# STM32U5Fx register map
File version: 1.0
CPU: CM33 r0p1, little endian, MPU, FPU, 4 interrupt priority bits
Registers are 32-bit, read-write, reset 0x0 unless marked. A register's access mark holds for its fields unless they carry their own. Offsets are from the block's base; [hi:lo] are bit positions; {n}, {i} and the like mark numbered series; 'fields as' and 'values as' point back to an identical list.

## FLASH
Base 0x40022000
Same registers: SEC_FLASH 0x50022000
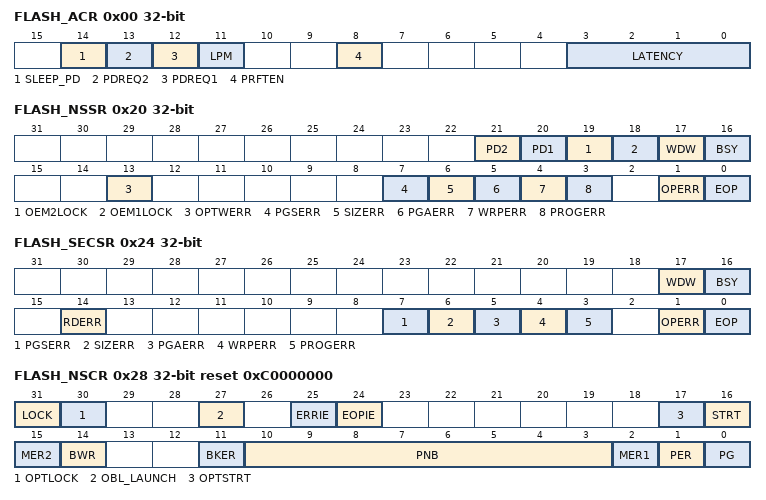
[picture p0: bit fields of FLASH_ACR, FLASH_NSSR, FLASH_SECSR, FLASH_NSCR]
0x00 FLASH_ACR — FLASH access control register
  [14] SLEEP_PD — Flash memory power-down mode during Sleep mode This bit determines whether the Flash memory is in power-down mode or Idle mode when the device is in Sleep mode. The Flash must not be put in power-down while a program or an erase operation is on-going.
    0=Flash in Idle mode during Sleep mode; 1=Flash in power-down mode during Sleep mode
  [13] PDREQ2 — Bank 2 power-down mode request This bit is write-protected with FLASH_PDKEY2R. This bit requests bank 2 to enter power-down mode. When bank 2 enters power-down mode, this bit is cleared by hardware and the PDKEY2R is locked.
    0=No request for bank 2 to enter power-down mode; 1=Bank 2 requested to enter power-down mode
  [12] PDREQ1 — Bank 1 power-down mode request This bit is write-protected with FLASH_PDKEY1R. This bit requests bank 1 to enter power-down mode. When bank 1 enters power-down mode, this bit is cleared by hardware and the PDKEY1R is locked.
    0=No request for bank 1 to enter power-down mode; 1=Bank 1 requested to enter power-down mode
  [11] LPM — Low-power read mode This bit puts the Flash memory in low-power read mode.
    0=Flash not in low-power read mode; 1=Flash in low-power read mode
  [8] PRFTEN — Prefetch enable This bit enables the prefetch buffer in the embedded Flash memory.
    0=Prefetch disabled; 1=Prefetch enabled
  [3:0] LATENCY — Latency These bits represent the ratio between the HCLK (AHB clock) period and the Flash memory access time. ...
    0=Zero wait state; 1=One wait state; 2=Two wait states; 15=Fifteen wait states
0x08 FLASH_NSKEYR wo — FLASH non-secure key register
  [31:0] NSKEY — Flash memory non-secure key The following values must be written consecutively to unlock the FLASH_NSCR register, allowing the Flash memory non-secure programming/erasing operations: KEY1: 0x4567 0123 KEY2: 0xCDEF 89AB
0x0C FLASH_SECKEYR wo — FLASH secure key register
  [31:0] SECKEY — Flash memory secure key The following values must be written consecutively to unlock the FLASH_SECCR register, allowing the Flash memory secure programming/erasing operations: KEY1: 0x4567 0123 KEY2: 0xCDEF 89AB
0x10 FLASH_OPTKEYR wo — FLASH option key register
  [31:0] OPTKEY — Option byte key The following values must be written consecutively to unlock the FLASH_OPTR register allowing option byte programming/erasing operations: KEY1: 0x0819 2A3B KEY2: 0x4C5D 6E7F
0x18 FLASH_PDKEY1R wo — FLASH bank 1 power-down key register
  [31:0] PDKEY1 — Bank 1 power-down key The following values must be written consecutively to unlock the PDREQ1 bit in FLASH_ACR: PDKEY1_1: 0x0415 2637 PDKEY1_2: 0xFAFB FCFD
0x1C FLASH_PDKEY2R wo — FLASH bank 2 power-down key register
  [31:0] PDKEY2 — Bank 2 power-down key The following values must be written consecutively to unlock the PDREQ2 bit in FLASH_ACR: PDKEY2_1: 0x4051 6273 PDKEY2_2: 0xAFBF CFDF
0x20 FLASH_NSSR (reset mask 0xFFF0FFFF) — FLASH non-secure status register
  [21] PD2 ro — Bank 2 in power-down mode This bit indicates that the Flash memory bank 2 is in power-down state. It is reset when bank 2 is in normal mode or being awaken.
  [20] PD1 ro — Bank 1 in power-down mode This bit indicates that the Flash memory bank 1 is in power-down state. It is reset when bank 1 is in normal mode or being awaken.
  [19] OEM2LOCK ro — OEM2 lock This bit indicates that the OEM2 RDP key read during the OBL is not virgin. When set, the OEM2 RDP lock mechanism is active.
  [18] OEM1LOCK ro — OEM1 lock This bit indicates that the OEM1 RDP key read during the OBL is not virgin. When set, the OEM1 RDP lock mechanism is active.
  [17] WDW ro — Non-secure wait data to write This bit indicates that the Flash memory write buffer has been written by a secure or non-secure operation. It is set when the first data is stored in the buffer and cleared when the write is performed in the Flash memory.
  [16] BSY ro — Non-secure busy This indicates that a Flash memory secure or non-secure operation is in progress. This bit is set at the beginning of a Flash operation and reset when the operation finishes or when an error occurs.
  [13] OPTWERR — Option write error This bit is set by hardware when the options bytes are written with an invalid configuration. It is cleared by writing 1. Refer to for full conditions of error flag setting.
  [7] PGSERR — Non-secure programming sequence error This bit is set by hardware when programming sequence is not correct. It is cleared by writing 1. Refer to for full conditions of error flag setting.
  [6] SIZERR — Non-secure size error This bit is set by hardware when the size of the access is a byte or half-word during a non-secure program sequence. Only quad-word programming is allowed by means of successive word accesses. This bit is cleared by writing 1.
  [5] PGAERR — Non-secure programming alignment error This bit is set by hardware when the first word to be programmed is not aligned with a quad-word address, or the second, third or forth word does not belong to the same quad-word address. This bit is cleared by writing 1.
  [4] WRPERR — Non-secure write protection error This bit is set by hardware when an non-secure address to be erased/programmed belongs to a write-protected part (by WRP, PCROP, HDP or RDP level 1) of the Flash memory. This bit is cleared by writing 1. Refer to for full conditions of error flag setting.
  [3] PROGERR — Non-secure programming error This bit is set by hardware when a non-secure quad-word address to be programmed contains a value different from all 1 before programming, except if the data to write is all 0. This bit is cleared by writing 1.
  [1] OPERR — Non-secure operation error This bit is set by hardware when a Flash memory non-secure operation (program/erase) completes unsuccessfully. This bit is set only if non-secure error interrupts are enabled (NSERRIE = 1). This bit is cleared by writing 1.
  [0] EOP — Non-secure end of operation This bit is set by hardware when one or more Flash memory non-secure operation (program/erase) has been completed successfully. This bit is set only if the non-secure end of operation interrupts are enabled (EOPIE = 1 in FLASH_NSCR). This bit is cleared by writing 1.
0x24 FLASH_SECSR — FLASH secure status register
  [17] WDW ro — Secure wait data to write This bit indicates that the Flash memory write buffer has been written by a secure or non-secure operation. It is set when the first data is stored in the buffer and cleared when the write is performed in the Flash memory.
  [16] BSY ro — Secure busy This bit indicates that a Flash memory secure or non-secure operation is in progress. This is set on the beginning of a Flash operation and reset when the operation finishes or when an error occurs.
  [14] RDERR — Secure readout protection error This bit is set by hardware when a read access is performed to a secure PCROP area and when a cacheable fetch access is performed to a secure PCROP area. An interrupt is generated if RDERRIE is set in FLASH_SECCR register. This bit is cleared by writing 1.
  [7] PGSERR — Secure programming sequence error This bit is set by hardware when programming sequence is not correct. It is cleared by writing 1. Refer to for full conditions of error flag setting.
  [6] SIZERR — Secure size error This bit is set by hardware when the size of the access is a byte or half-word during a secure program sequence. Only quad-word programming is allowed by means of successive word accesses.This bit is cleared by writing 1.
  [5] PGAERR — Secure programming alignment error This bit is set by hardware when the first word to be programmed is not aligned with a quad-word address, or the second, third or forth word does not belong to the same quad-word address.This bit is cleared by writing 1.
  [4] WRPERR — Secure write protection error This bit is set by hardware when an secure address to be erased/programmed belongs to a write-protected part (by WRP, PCROP, HDP or RDP level 1) of the Flash memory.This bit is cleared by writing 1. Refer to for full conditions of error flag setting.
  [3] PROGERR — Secure programming error This bit is set by hardware when a secure quad-word address to be programmed contains a value different from all 1 before programming, except if the data to write is all 0. This bit is cleared by writing 1.
  [1] OPERR — Secure operation error This bit is set by hardware when a Flash memory secure operation (program/erase) completes unsuccessfully. This bit is set only if secure error interrupts are enabled (SECERRIE = 1). This bit is cleared by writing 1.
  [0] EOP — Secure end of operation This bit is set by hardware when one or more Flash memory secure operation (program/erase) has been completed successfully. This bit is set only if the secure end of operation interrupts are enabled (EOPIE = 1 in FLASH_SECCR). This bit is cleared by writing 1.
0x28 FLASH_NSCR reset 0xC0000000 — FLASH non-secure control register
  [31] LOCK — Non-secure lock This bit is set only. When set, the FLASH_NSCR register is locked. It is cleared by hardware after detecting the unlock sequence in FLASH_NSKEYR register. In case of an unsuccessful unlock operation, this bit remains set until the next system reset.
  [30] OPTLOCK — Option lock This bit is set only. When set, all bits concerning user options in FLASH_NSCR register are locked. This bit is cleared by hardware after detecting the unlock sequence. The LOCK bit in the FLASH_NSCR must be cleared before doing the unlock sequence for OPTLOCK bit. In case of an unsuccessful unlock operation, this bit remains set until the next reset.
  [27] OBL_LAUNCH — Force the option byte loading When set to 1, this bit forces the option byte reloading. This bit is cleared only when the option byte loading is complete. It cannot be written if OPTLOCK is set.
    0=Option byte loading complete; 1=Option byte loading requested
  [25] ERRIE — Non-secure error interrupt enable This bit enables the interrupt generation when the OPERR bit in the FLASH_NSSR is set to 1.
    0=Non-secure OPERR error interrupt disabled; 1=Non-secure OPERR error interrupt enabled
  [24] EOPIE — Non-secure end of operation interrupt enable This bit enables the interrupt generation when the EOP bit in the FLASH_NSSR is set to 1.
    0=Non-secure EOP Interrupt disabled; 1=Non-secure EOP Interrupt enabled
  [17] OPTSTRT — Options modification start This bit triggers an options operation when set. It can not be written if OPTLOCK bit is set. This bit is set only by software, and is cleared when the BSY bit is cleared in FLASH_NSSR.
  [16] STRT — Non-secure start This bit triggers a non-secure erase operation when set. If MER1, MER2 and PER bits are reset and the STRT bit is set, the PGSERR bit in FLASH_NSSR is set (this condition is forbidden). This bit is set only by software and is cleared when the BSY bit is cleared in FLASH_NSSR.
  [15] MER2 — Non-secure bank 2 mass erase This bit triggers the bank 2 non-secure mass erase (all bank 2 user pages) when set.
  [14] BWR — Non-secure burst write programming mode When set, this bit selects the burst write programming mode.
  [11] BKER — Non-secure bank selection for page erase
    0=Bank 1 selected for non-secure page erase; 1=Bank 2 selected for non-secure page erase
  [10:3] PNB — Non-secure page number selection These bits select the page to erase. ... ...
    0=page 0; 1=page 1; 127=page 127 (upper page for STM32U575/585); 255=page 255 (upper page for STM32U59x/5Ax)
  [2] MER1 — Non-secure bank 1 mass erase This bit triggers the bank 1 non-secure mass erase (all bank 1 user pages) when set.
  [1] PER — Non-secure page erase
    0=Non-secure page erase disabled; 1=Non-secure page erase enabled
  [0] PG — Non-secure programming
    0=Non-secure Flash programming disabled; 1=Non-secure Flash programming enabled
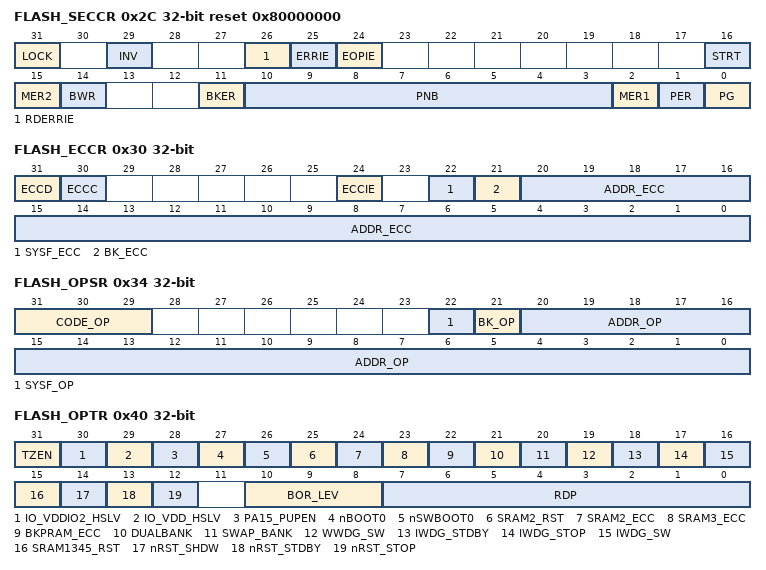
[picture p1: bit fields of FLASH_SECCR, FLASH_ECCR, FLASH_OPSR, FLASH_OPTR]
0x2C FLASH_SECCR reset 0x80000000 — FLASH secure control register
  [31] LOCK — Secure lock This bit is set only. When set, the FLASH_SECCR register is locked. It is cleared by hardware after detecting the unlock sequence in FLASH_SECKEYR register. In case of an unsuccessful unlock operation, this bit remains set until the next system reset.
  [29] INV — Flash memory security state invert This bit inverts the Flash memory security state.
  [26] RDERRIE — Secure PCROP read error interrupt enable This bit enables the interrupt generation when the RDERR bit in the FLASH_SECSR is set to 1.
    0=Secure PCROP read error interrupt disabled; 1=Secure PCROP read error interrupt enabled
  [25] ERRIE — Secure error interrupt enable This bit enables the interrupt generation when the OPERR bit in the FLASH_SECSR is set to 1.
    0=Secure OPERR error interrupt disabled; 1=Secure OPERR error interrupt enabled
  [24] EOPIE — Secure End of operation interrupt enable This bit enables the interrupt generation when the EOP bit in the FLASH_SECSR is set to 1.
    0=Secure EOP Interrupt disabled; 1=Secure EOP Interrupt enabled
  [16] STRT — Secure start This bit triggers a secure erase operation when set. If MER1, MER2 and PER bits are reset and the STRT bit is set, the PGSERR in the FLASH_SECSR is set (this condition is forbidden). This bit is set only by software and is cleared when the BSY bit is cleared in FLASH_SECSR.
  [15] MER2 — Secure bank 2 mass erase This bit triggers the bank 2 secure mass erase (all bank 2 user pages) when set.
  [14] BWR — Secure burst write programming mode When set, this bit selects the burst write programming mode.
  [11] BKER — Secure bank selection for page erase
    0=Bank 1 selected for secure page erase; 1=Bank 2 selected for secure page erase
  [10:3] PNB — Secure page number selection These bits select the page to erase. ... ...
    values as FLASH_NSCR.PNB
  [2] MER1 — Secure bank 1 mass erase This bit triggers the bank 1 secure mass erase (all bank 1 user pages) when set.
  [1] PER — Secure page erase
    0=Secure page erase disabled; 1=Secure page erase enabled
  [0] PG — Secure programming
    0=Secure Flash programming disabled; 1=Secure Flash programming enabled
0x30 FLASH_ECCR — FLASH ECC register
  [31] ECCD — ECC detection This bit is set by hardware when two ECC errors have been detected (only if ECCC and ECCD were previously cleared). When this bit is set, a NMI is generated. This bit is cleared by writing 1.
  [30] ECCC — ECC correction This bit is set by hardware when one ECC error has been detected and corrected (only if ECCC and ECCD were previously cleared). An interrupt is generated if ECCIE is set. This bit is cleared by writing 1.
  [24] ECCIE — ECC correction interrupt enable This bit enables the interrupt generation when the ECCC bit in the FLASH_ECCR register is set.
    0=ECCC interrupt disabled; 1=ECCC interrupt enabled
  [22] SYSF_ECC ro — System Flash memory ECC fail This bit indicates that the ECC error correction or double ECC error detection is located in the system Flash memory.
  [21] BK_ECC ro — ECC fail bank This bit indicates which bank is concerned by the ECC error correction or by the double ECC error detection.
    0=Bank 1; 1=Bank 2
  [20:0] ADDR_ECC ro — ECC fail address This field indicates which address is concerned by the ECC error correction or by the double ECC error detection. The address is given by bank from address 0x0 0000 to 0x1F FFF0.
0x34 FLASH_OPSR ro (reset mask 0xF000000) — FLASH operation status register
  [31:29] CODE_OP — Flash memory operation code This field indicates which Flash memory operation has been interrupted by a system reset:
    0=No Flash operation interrupted by previous reset; 1=Single write operation interrupted; 2=Burst write operation interrupted; 3=Page erase operation interrupted; 4=Bank erase operation interrupted; 5=Mass erase operation interrupted; 6=Option change operation interrupted
  [22] SYSF_OP — Operation in system Flash memory interrupted This bit indicates that the reset occurred during an operation in the system Flash memory.
  [21] BK_OP — Interrupted operation bank This bit indicates which Flash memory bank was accessed when reset occurred
    0=Bank 1; 1=Bank 2
  [20:0] ADDR_OP — Interrupted operation address This field indicates which address in the Flash memory was accessed when reset occurred. The address is given by bank from address 0x0 0000 to 0x1F FFF0.
0x40 FLASH_OPTR reset not defined — FLASH option register
  [31] TZEN — Global TrustZone security enable
    0=Global TrustZone security disabled; 1=Global TrustZone security enabled
  [30] IO_VDDIO2_HSLV — High-speed IO at low VDDIO2 voltage configuration bit This bit can be set only with VDDIO2 below 2.5 V.
    0=High-speed IO at low VDDIO2 voltage feature disabled (VDDIO2 can exceed 2.5 V); 1=High-speed IO at low VDDIO2 voltage feature enabled (VDDIO2 remains below 2.5 V)
  [29] IO_VDD_HSLV — High-speed IO at low VDD voltage configuration bit This bit can be set only with VDD below 2.5V
    0=High-speed IO at low VDD voltage feature disabled (VDD can exceed 2.5 V); 1=High-speed IO at low VDD voltage feature enabled (VDD remains below 2.5 V)
  [28] PA15_PUPEN — PA15 pull-up enable
    0=USB power delivery dead-battery enabled/TDI pull-up deactivated; 1=USB power delivery dead-battery disabled/TDI pull-up activated
  [27] nBOOT0 — nBOOT0 option bit
    0=nBOOT0 = 0; 1=nBOOT0 = 1
  [26] nSWBOOT0 — Software BOOT0
    0=BOOT0 taken from the option bit nBOOT0; 1=BOOT0 taken from PH3/BOOT0 pin
  [25] SRAM2_RST — SRAM2 erase when system reset
    0=SRAM2 erased when a system reset occurs; 1=SRAM2 not erased when a system reset occurs
  [24] SRAM2_ECC — SRAM2 ECC detection and correction enable
    0=SRAM2 ECC check enabled; 1=SRAM2 ECC check disabled
  [23] SRAM3_ECC — SRAM3 ECC detection and correction enable
    0=SRAM3 ECC check enabled; 1=SRAM3 ECC check disabled
  [22] BKPRAM_ECC — Backup RAM ECC detection and correction enable
    0=Backup RAM ECC check enabled; 1=Backup RAM ECC check disabled
  [21] DUALBANK — Dual-bank on 1-Mbyte and 512-Kbyte Flash memory devices
    0=Single bank Flash with contiguous address in bank 1; 1=Dual-bank Flash with contiguous addresses
  [20] SWAP_BANK — Swap banks
    0=Bank 1 and bank 2 addresses not swapped; 1=Bank 1 and bank 2 addresses swapped
  [19] WWDG_SW — Window watchdog selection
    0=Hardware window watchdog selected; 1=Software window watchdog selected
  [18] IWDG_STDBY — Independent watchdog counter freeze in Standby mode
    0=Independent watchdog counter frozen in Standby mode; 1=Independent watchdog counter running in Standby mode
  [17] IWDG_STOP — Independent watchdog counter freeze in Stop mode
    0=Independent watchdog counter frozen in Stop mode; 1=Independent watchdog counter running in Stop mode
  [16] IWDG_SW — Independent watchdog selection
    0=Hardware independent watchdog selected; 1=Software independent watchdog selected
  [15] SRAM1345_RST — SRAM1, SRAM3, SRAM4 and SRAM5 erase upon system reset
    0=SRAM1, SRAM3, SRAM4 and SRAM5 erased when a system reset occurs; 1=SRAM1, SRAM3, SRAM4 and SRAM5 not erased when a system reset occurs
  [14] nRST_SHDW — Reset generation in Shutdown mode
    0=Reset generated when entering the Shutdown mode; 1=No reset generated when entering the Shutdown mode
  [13] nRST_STDBY — Reset generation in Standby mode
    0=Reset generated when entering the Standby mode; 1=No reset generate when entering the Standby mode
  [12] nRST_STOP — Reset generation in Stop mode
    0=Reset generated when entering the Stop mode; 1=No reset generated when entering the Stop mode
  [10:8] BOR_LEV — BOR reset level These bits contain the VDD supply level threshold that activates/releases the reset.
    0=BOR level 0 (reset level threshold around 1.7 V); 1=BOR level 1 (reset level threshold around 2.0 V); 2=BOR level 2 (reset level threshold around 2.2 V); 3=BOR level 3 (reset level threshold around 2.5 V); 4=BOR level 4 (reset level threshold around 2.8 V)
  [7:0] RDP — Readout protection level Others: Level 1 (memories readout protection active) Note: Refer to for more details.
    170=Level 0 (readout protection not active); 85=Level 0.5 (readout protection not active, only non-secure debug access is possible). Only available when TrustZone is active (TZEN=1); 204=Level 2 (chip readout protection active)
0x44 FLASH_NSBOOTADD0R reset 0xF (reset mask 0xF) — FLASH non-secure boot address 0 register
  [31:7] NSBOOTADD0 — Non-secure boot base address 0 The non-secure boot memory address can be programmed to any address in the valid address range with a granularity of 128 bytes. These bits correspond to address [31:7]. The NSBOOTADD0 option bytes are selected following the BOOT0 pin or nSWBOOT0 state. Examples: NSBOOTADD0[24:0] = 0x0100000: Boot from non-secure Flash memory (0x0800 0000) NSBOOTADD0[24:0] = 0x017F200: Boot from system memory bootloader (0x0BF9 0000) NSBOOTADD0[24:0] = 0x0400000: Boot from non-secure SRAM1 on S-Bus (0x2000 0000)
0x48 FLASH_NSBOOTADD1R reset 0xF (reset mask 0xF) — FLASH non-secure boot address 1 register
  [31:7] NSBOOTADD1 — Non-secure boot address 1 The non-secure boot memory address can be programmed to any address in the valid address range with a granularity of 128 bytes. These bits correspond to address [31:7]. The NSBOOTADD0 option bytes are selected following the BOOT0 pin or nSWBOOT0 state. Examples: NSBOOTADD1[24:0] = 0x0100000: Boot from non-secure Flash memory (0x0800 0000) NSBOOTADD1[24:0] = 0x017F200: Boot from system memory bootloader (0x0BF9 0000) NSBOOTADD1[24:0] = 0x0400000: Boot from non-secure SRAM1 on S-Bus (0x2000 0000)
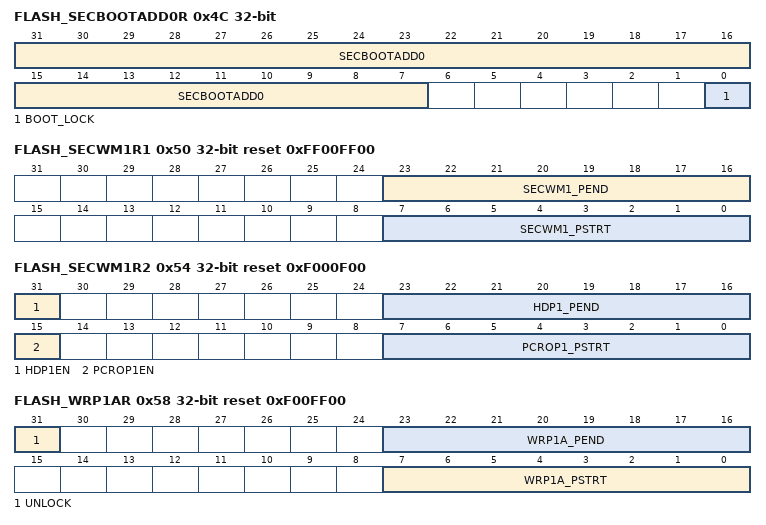
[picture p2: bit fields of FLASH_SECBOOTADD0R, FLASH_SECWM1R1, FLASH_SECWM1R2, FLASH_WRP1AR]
0x4C FLASH_SECBOOTADD0R reset not defined — FLASH secure boot address 0 register
  [31:7] SECBOOTADD0 — Secure boot base address 0 The secure boot memory address can be programmed to any address in the valid address range with a granularity of 128 bytes. This bits correspond to address [31:7] The SECBOOTADD0 option bytes are selected following the BOOT0 pin or nSWBOOT0 state. Examples: SECBOOTADD0[24:0] = 0x018 0000: Boot from secure Flash memory (0x0C00 0000) SECBOOTADD0[24:0] = 0x01F F000: Boot from RSS (0x0FF8 0000) SECBOOTADD0[24:0] = 0x060 0000: Boot from secure SRAM1 on S-Bus (0x3000 0000)
  [0] BOOT_LOCK — Boot lock When set, the boot is always forced to base address value programmed in SECBOOTADD0[24:0] option bytes whatever the boot selection option. When set, this bit can only be cleared by an RDP at level 0.
0x50 FLASH_SECWM1R1 reset 0xFF00FF00 (reset mask 0xFF00FF00) — FLASH secure watermark1 register 1
  [23:16] SECWM1_PEND — End page of first secure area This field contains the last page of the secure area in bank 1.
  [7:0] SECWM1_PSTRT — Start page of first secure area This field contains the first page of the secure area in bank 1.
0x54 FLASH_SECWM1R2 reset 0xF000F00 (reset mask 0xF000F00) — FLASH secure watermark1 register 2
  [31] HDP1EN — Hide protection first area enable
    0=No HDP area 1; 1=HDP first area enabled
  [23:16] HDP1_PEND — End page of first hide protection area This field contains the last page of the HDP area in bank 1.
  [15] PCROP1EN — PCROP1 area enable
    0=PCROP1 area disabled; 1=PCROP1 area enabled
  [7:0] PCROP1_PSTRT — Start page of first PCROP area This field contains the first page of the PCROP area in bank 1.
0x58 FLASH_WRP1AR reset 0xF00FF00 (reset mask 0xF00FF00) — FLASH WRP1 area A address register
  [31] UNLOCK — Bank 1 WPR first area A unlock
    0=WRP1A start and end pages locked; 1=WRP1A start and end pages unlocked
  [23:16] WRP1A_PEND — Bank 1 WPR first area A end page This field contains the last page of the first WPR area in bank 1.
  [7:0] WRP1A_PSTRT — bank 1 WPR first area A start page This field contains the first page of the first WPR area for bank 1.
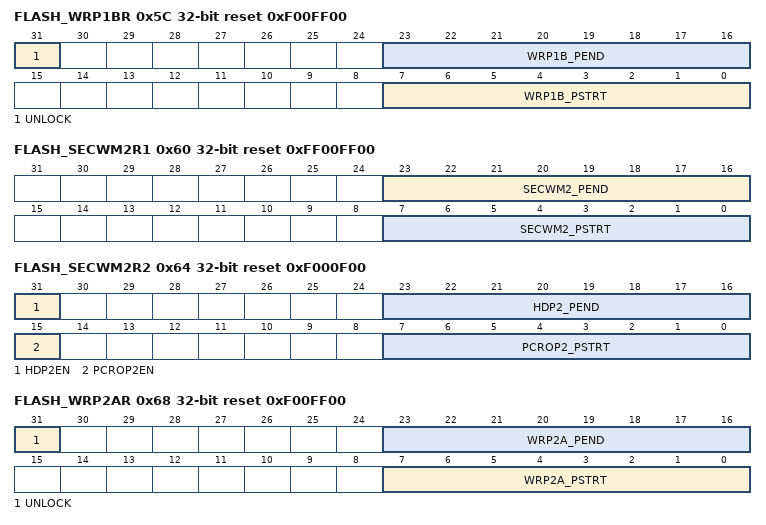
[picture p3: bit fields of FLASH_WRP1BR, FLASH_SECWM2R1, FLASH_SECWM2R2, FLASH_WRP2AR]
0x5C FLASH_WRP1BR reset 0xF00FF00 (reset mask 0xF00FF00) — FLASH WRP1 area B address register
  [31] UNLOCK — Bank 1 WPR second area B unlock
    0=WRP1B start and end pages locked; 1=WRP1B start and end pages unlocked
  [23:16] WRP1B_PEND — Bank 1 WRP second area B end page This field contains the last page of the second WRP area in bank 1.
  [7:0] WRP1B_PSTRT — Bank 1 WRP second area B start page This field contains the first page of the second WRP area for bank 1.
0x60 FLASH_SECWM2R1 reset 0xFF00FF00 (reset mask 0xFF00FF00) — FLASH secure watermark2 register 1
  [23:16] SECWM2_PEND — End page of second secure area This field contains the last page of the secure area in bank 2.
  [7:0] SECWM2_PSTRT — Start page of second secure area This field contains the first page of the secure area in bank 2.
0x64 FLASH_SECWM2R2 reset 0xF000F00 (reset mask 0xF000F00) — FLASH secure watermark2 register 2
  [31] HDP2EN — Hide protection second area enable
    0=No HDP area 2; 1=HDP second area is enabled
  [23:16] HDP2_PEND — End page of hide protection second area HDP2_PEND contains the last page of the HDP area in bank 2.
  [15] PCROP2EN — PCROP2 area enable
    0=PCROP2 area is disabled; 1=PCROP2 area is enabled
  [7:0] PCROP2_PSTRT — Start page of PCROP2 area PRCROP2_PSTRT contains the first page of the PCROP area in bank 2.
0x68 FLASH_WRP2AR reset 0xF00FF00 (reset mask 0xF00FF00) — FLASH WPR2 area A address register
  [31] UNLOCK — Bank 2 WPR first area A unlock
    0=WRP2A start and end pages locked; 1=WRP2A start and end pages unlocked
  [23:16] WRP2A_PEND — Bank 2 WPR first area A end page This field contains the last page of the first WRP area in bank 2.
  [7:0] WRP2A_PSTRT — Bank 2 WPR first area A start page This field contains the first page of the first WRP area for bank 2.
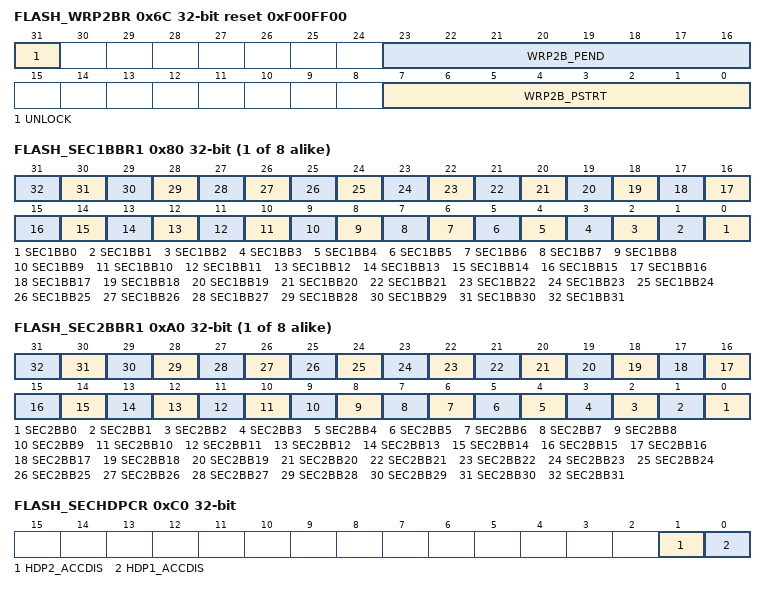
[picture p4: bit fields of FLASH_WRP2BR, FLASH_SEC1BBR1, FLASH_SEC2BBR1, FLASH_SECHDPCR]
0x6C FLASH_WRP2BR reset 0xF00FF00 (reset mask 0xF00FF00) — FLASH WPR2 area B address register
  [31] UNLOCK — Bank 2 WPR second area B unlock
    0=WRP2B start and end pages locked; 1=WRP2B start and end pages unlocked
  [23:16] WRP2B_PEND — Bank 2 WPR second area B end page This field contains the last page of the second WRP area in bank 2.
  [7:0] WRP2B_PSTRT — Bank 2 WPR second area B start page This field contains the first page of the second WRP area for bank 2.
0x70 FLASH_OEM1KEYR1 wo — FLASH OEM1 key register 1
  [31:0] OEM1KEY — OEM1 least significant bytes key
0x74 FLASH_OEM1KEYR2 wo — FLASH OEM1 key register 2
  [31:0] OEM1KEY — OEM1 most significant bytes key
0x78 FLASH_OEM2KEYR1 wo — FLASH OEM2 key register 1
  [31:0] OEM2KEY — OEM2 least significant bytes key
0x7C FLASH_OEM2KEYR2 wo — FLASH OEM2 key register 2
  [31:0] OEM2KEY — OEM2 most significant bytes key
{0x7C+4i} FLASH_SEC1BBR{i} (i=1..8) — FLASH secure block based bank 1 register {i}
  [n] SEC1BB{n} (n=0..31)
{0x9C+4i} FLASH_SEC2BBR{i} (i=1..8) — FLASH secure block based bank 2 register {i}
  [n] SEC2BB{n} (n=0..31)
0xC0 FLASH_SECHDPCR — FLASH secure HDP control register
  [1] HDP2_ACCDIS — HDP2 area access disable When set, this bit is only cleared by a system reset.
    0=Access to HDP2 area granted; 1=Access to HDP2 area denied (SECWM2Ry option bytes modification bocked -refer to )
  [0] HDP1_ACCDIS — HDP1 area access disable When set, this bit is only cleared by a system reset.
    0=Access to HDP1 area granted; 1=Access to HDP1 area denied (SECWM1Ry option bytes modification blocked - refer to )
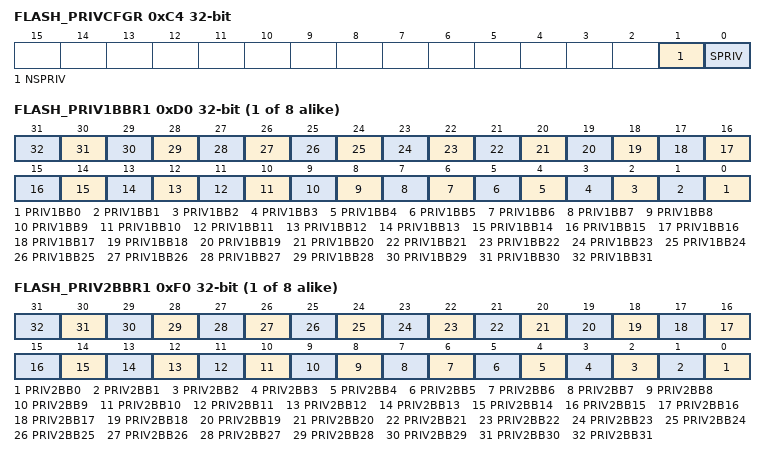
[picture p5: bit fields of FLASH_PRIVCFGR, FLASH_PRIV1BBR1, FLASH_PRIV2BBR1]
0xC4 FLASH_PRIVCFGR — FLASH privilege configuration register
  [1] NSPRIV — Privileged protection for non-secure registers
  [0] SPRIV — Privileged protection for secure registers
{0xCC+4i} FLASH_PRIV1BBR{i} (i=1..8) — FLASH privilege block based bank 1 register {i}
  [n] PRIV1BB{n} (n=0..31)
{0xEC+4i} FLASH_PRIV2BBR{i} (i=1..8) — FLASH privilege block based bank 2 register {i}
  [n] PRIV2BB{n} (n=0..31)
